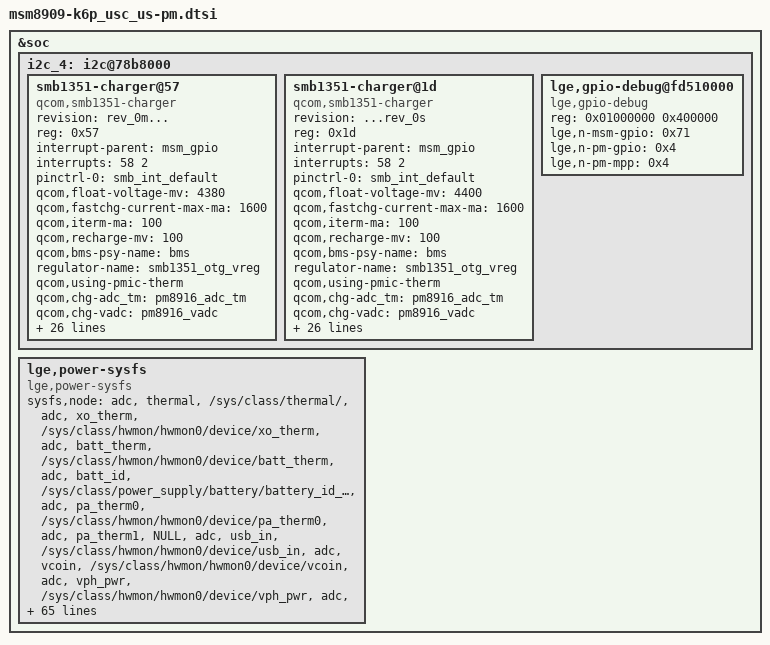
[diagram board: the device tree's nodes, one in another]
/* Copyright (c) 2014, The Linux Foundation. All rights reserved.
 *
 * This program is free software; you can redistribute it and/or modify
 * it under the terms of the GNU General Public License version 2 and
 * only version 2 as published by the Free Software Foundation.
 *
 * This program is distributed in the hope that it will be useful,
 * but WITHOUT ANY WARRANTY; without even the implied warranty of
 * MERCHANTABILITY or FITNESS FOR A PARTICULAR PURPOSE.  See the
 * GNU General Public License for more details.
 */

&soc {
	i2c_4: i2c@78b8000 { /* BLSP4 : BLSP4 QUP3 */
		/* BLSP1 QUP4 */
		status = "ok";

		smb1351-charger@57 {
			revision = "rev_0m...";
			status = "ok";
			compatible = "qcom,smb1351-charger";
			reg = <0x57>;
			interrupt-parent = <&msm_gpio>;
			interrupts = <58 2>;
			pinctrl-names = "default";
			pinctrl-0 = <&smb_int_default>;
			qcom,float-voltage-mv = <4380>;
			qcom,fastchg-current-max-ma = <1600>;
			qcom,iterm-ma = <100>;
			qcom,recharge-mv = <100>;
			qcom,bms-psy-name = "bms";
			regulator-name = "smb1351_otg_vreg";
			qcom,using-pmic-therm;
			qcom,chg-adc_tm = <&pm8916_adc_tm>;
			qcom,chg-vadc = <&pm8916_vadc>;
			qcom,clk-freq-out = <100000>;
			qcom,clk-freq-in  = <19200000>;
			qcom,batt-hot-decidegc = <550>;
			qcom,batt-cold-decidegc = <0>;
			qcom,batt-missing-decidegc = <(-200)>;
			qcom,batt-warm-decidegc = <500>;
			qcom,batt-cool-decidegc = <50>;
			qcom,batt-warm-ma = <350>;
			qcom,batt-cool-ma = <350>;
			qcom,batt-warm-mv = <4200>;
			qcom,batt-cool-mv = <4200>;

			/* Each model is defferently value */
			lge,no-init-cable = <0 0 0>;
			lge,cable-mhl-1k = <5000 500 500>;
			lge,cable-u-28p7k = <10000 1200 500>;
			lge,cable-28p7k = <250000 1200 500>;
			lge,cable-56k = <600000 1500 1500>;
			lge,cable-100k = <620000 1200 500>;
			lge,cable-130k = <780000 1500 1500>;
			lge,cable-180k = <870000 1200 500>;
			lge,cable-200k = <910000 1200 500>;
			lge,cable-220k = <960000 1200 500>;
			lge,cable-270k = <1050000 1200 500>;
			lge,cable-330k = <1150000 1200 500>;
			lge,cable-620k = <1380000 1200 500>;
			lge,cable-910k = <1630000 1500 1500>;
			lge,cable-none = <1900000 1800  500>;
		};

		smb1351-charger@1d {
			revision = "...rev_0s";
			status = "ok";
			compatible = "qcom,smb1351-charger";
			reg = <0x1d>;
			interrupt-parent = <&msm_gpio>;
			interrupts = <58 2>;
			pinctrl-names = "default";
			pinctrl-0 = <&smb_int_default>;
			qcom,float-voltage-mv = <4400>;
			qcom,fastchg-current-max-ma = <1600>;
			qcom,iterm-ma = <100>;
			qcom,recharge-mv = <100>;
			qcom,bms-psy-name = "bms";
			regulator-name = "smb1351_otg_vreg";
			qcom,using-pmic-therm;
			qcom,chg-adc_tm = <&pm8916_adc_tm>;
			qcom,chg-vadc = <&pm8916_vadc>;
			qcom,clk-freq-out = <100000>;
			qcom,clk-freq-in  = <19200000>;
			qcom,batt-hot-decidegc = <550>;
			qcom,batt-cold-decidegc = <0>;
			qcom,batt-missing-decidegc = <(-200)>;
			qcom,batt-warm-decidegc = <500>;
			qcom,batt-cool-decidegc = <50>;
			qcom,batt-warm-ma = <350>;
			qcom,batt-cool-ma = <350>;
			qcom,batt-warm-mv = <4200>;
			qcom,batt-cool-mv = <4200>;

			/* Each model is defferently value */
			lge,no-init-cable = <0 0 0>;
			lge,cable-mhl-1k = <5000 500 500>;
			lge,cable-u-28p7k = <10000 1200 500>;
			lge,cable-28p7k = <250000 1200 500>;
			lge,cable-56k = <600000 1500 1500>;
			lge,cable-100k = <620000 1200 500>;
			lge,cable-130k = <780000 1500 1500>;
			lge,cable-180k = <870000 1200 500>;
			lge,cable-200k = <910000 1200 500>;
			lge,cable-220k = <960000 1200 500>;
			lge,cable-270k = <1050000 1200 500>;
			lge,cable-330k = <1150000 1200 500>;
			lge,cable-620k = <1380000 1200 500>;
			lge,cable-910k = <1630000 1500 1500>;
			lge,cable-none = <1900000 3000  500>;
		};

		lge,gpio-debug@fd510000 {
			compatible = "lge,gpio-debug";
			reg = <0x01000000 0x400000>;
			reg-names = "tlmm-base";
			lge,n-msm-gpio = <0x71>;
			lge,n-pm-gpio = <0x4>;
			lge,n-pm-mpp = <0x4>;
		};
	};
};

&soc {
	lge,power-sysfs {
		compatible = "lge,power-sysfs";

		sysfs,node =
			/* group , user_node,  kernel node */
			/* ADC/MPP */
			"adc", "thermal", "/sys/class/thermal/",
			"adc", "xo_therm", "/sys/class/hwmon/hwmon0/device/xo_therm",
			"adc", "batt_therm", "/sys/class/hwmon/hwmon0/device/batt_therm",
			"adc", "batt_id", "/sys/class/power_supply/battery/battery_id_checker",
			"adc", "pa_therm0", "/sys/class/hwmon/hwmon0/device/pa_therm0",
			"adc", "pa_therm1", "NULL",
			"adc", "usb_in", "/sys/class/hwmon/hwmon0/device/usb_in",
			"adc", "vcoin", "/sys/class/hwmon/hwmon0/device/vcoin",
			"adc", "vph_pwr", "/sys/class/hwmon/hwmon0/device/vph_pwr",
			"adc", "usb_id", "/sys/class/hwmon/hwmon0/device/usb_id",
			/* Battery */
			"battery", "capacity", "/sys/class/power_supply/battery/capacity",
			"battery", "health", "/sys/class/power_supply/battery/health",
			"battery", "present", "/sys/class/power_supply/battery/present",
			"battery", "pseudo_batt", "/sys/class/power_supply/battery/pseudo_batt",
			"battery", "status", "/sys/class/power_supply/battery/status",
			"battery", "temp", "/sys/class/power_supply/battery/temp",
			"battery", "valid_batt_id", "/sys/class/power_supply/battery/valid_batt_id",
			"battery", "voltage_now", "/sys/class/power_supply/battery/voltage_now",
			/* Charger */
			"charger", "ac_online", "NULL",
			"charger", "usb_online", "/sys/class/power_supply/usb/online",
			"charger", "present", "/sys/class/power_supply/usb/present",
			"charger", "wlc_online", "NULL",
			"charger", "type", "/sys/class/power_supply/usb/type",
			"charger", "time_out", "NULL",
			"charger", "charging_enabled", "/sys/class/power_supply/battery/charging_enabled",
			"charger", "ibat_current", "/sys/class/power_supply/battery/current_now",
			"charger", "ichg_current", "/sys/class/power_supply/usb/current_max",
			"charger", "iusb_control", "NULL",
			"charger", "thermal_mitigation", "/sys/module/qpnp_linear_charger/parameters/qpnp_thermal_mitigation",
			"charger", "wlc_thermal_mitigation", "NULL",
			"charger", "usb_parallel_chg_status", "NULL",
			"charger", "usb_parallel_charging_enabled", "NULL",
			/* LCD Backlight */
			"lcd", "brightness", "/sys/class/leds/lcd-backlight/brightness",
			"lcd", "max_brightness", "/sys/class/leds/lcd-backlight/max_brightness",
			/* KEY LED */
			"key_led", "red_brightness", "/sys/class/leds/R/brightness",
			"key_led", "green_brightness", "/sys/class/leds/G/brightness",
			"key_led", "blue_brightness", "/sys/class/leds/B/brightness",
			/* CPU */
			"cpu", "cpu_idle_modes", "NULL",
			/* GPU */
			"gpu", "busy", "/sys/class/kgsl/kgsl-3d0/gpubusy",
			/* PLATFORM */
			"platform", "speed_bin", "NULL",
			"platform", "pvs_bin", "NULL",
			"platform", "power_state", "/sys/power/autosleep",
			"platform", "poweron_alarm", "/sys/module/qpnp_rtc/parameters/poweron_alarm",
			"platform", "pcb_rev", "/sys/class/hwmon/hwmon0/device/pcb_rev",
			/* testmode */
			"testmode", "charge", "/sys/class/power_supply/battery/device/at_charge",
			"testmode", "chcomp", "/sys/class/power_supply/battery/device/at_chcomp",
			"testmode", "chgmodeoff", "/sys/class/power_supply/battery/charging_enabled",
			"testmode", "fuelrst", "NULL",
			"testmode", "rtc_time", "/dev/rtc0",
			"testmode", "pmrst", "NULL",
			"testmode", "battexit", "/sys/class/power_supply/battery/present"
			;
	};
};
